# RTS5921 register map
Vendor: Realtek Semiconductor Corp.; Series: RTS5921 Series; File version: 0.01
CPU: ARMV8MBL r0p0, little endian, MPU, no FPU, VTOR, 3 interrupt priority bits
Registers are 32-bit, read-write, reset 0x0 unless marked. A register's access mark holds for its fields unless they carry their own. Offsets are from the block's base; [hi:lo] are bit positions; {n}, {i} and the like mark numbered series.

## GPIO — GPIO Controller
Base 0x40110000
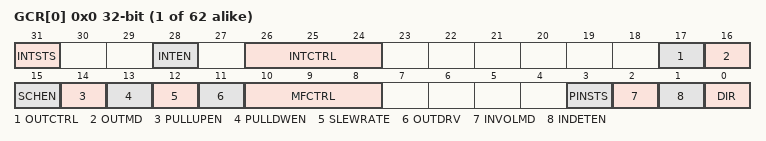
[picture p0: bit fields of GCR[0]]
{0x0+4i} GCR[{i}] (i=0..61) — CONTROL REGISTER
  [31] INTSTS write-1-clears — Interrupt Status
    0=NOT_OCCURRED (GPIO interrupt is not occurred); 1=OCCURRED (GPIO interrupt is occurred)
  [28] INTEN — Interrupt Enable
    0=DISABLE (Disable interrupt); 1=ENABLE (Enable interrupt)
  [26:24] INTCTRL — Type of GPIO Interrupt
    0=POSTIVE (Trigger interrupt when positive edge occurred); 1=NEGATIVE (Trigger interrupt when negative edge occurred); 2=DUAL (Trigger interrupt when positive/negative edge occurred); 3=LOW (Trigger interrupt when low-level occurred); 4=HIGH (Trigger interrupt when high-level occurred)
  [17] OUTCTRL — Output Control
    0=LOW (Output low); 1=HIGH (Output high)
  [16] OUTMD — Output Mode Selection
    0=PUSH_PULL (Push-pull mode); 1=OPEN_DRAIN (Open-drain mode)
  [15] SCHEN — Schmitter-Trigger Enable
    0=DISABLE (Disable schmitter-trigger); 1=ENABLE (Enable schmitter-trigger)
  [14] PULLUPEN — Internal Pull-Up Resistor Enable
    0=DISABLE (Disable internal pull-up resistor); 1=ENABLE (Enable internal pull-up resistor)
  [13] PULLDWEN — Internal Pull-Down Resistor Enable
    0=DISABLE (Disable internal pull-down resistor); 1=ENABLE (Enable internal pull-down resistor)
  [12] SLEWRATE — Slew Rate Selection
    0=FAST (Fast slew-rate); 1=SLOW (Slow slew-rate)
  [11] OUTDRV — Driving Current Selection
    0=LOW (Low driving capability); 1=HIGH (High driving capability)
  [10:8] MFCTRL — Multiple Function Control
    {v}=FUN{v} (Select function[{v}]) (v=0..3)
  [3] PINSTS ro — Status of GPIO Pin
    0=LOW (Pin status is low); 1=HIGH (Pin status is high)
  [2] INVOLMD — Input Voltage Mode
    0=3V3 (3V3 voltage input); 1=1V8 (1V8 voltage input)
  [1] INDETEN — Input Detection Enable
    0=DISABLE (Disable input detection); 1=ENABLE (Enable input detection)
  [0] DIR — Direction
    0=INPUT (Intput mode); 1=OUTPUT (Output mode)

## LED0 — PWM LED Controller
Base 0x40121000
Same registers: LED1 0x40121020
0x00 MODE
  [1:0] SEL — Mode Selection
    0=OFF (PWMLED ouput is off); 1=BREATHING (PWMLED is under breathing mode); 2=BLINKING (PWMLED is under blinking mode); 3=ALWAYS_ON (PWMLED ouput is always on)
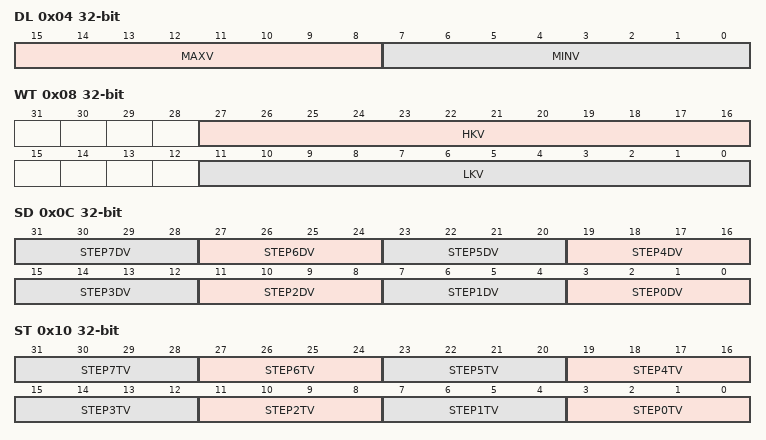
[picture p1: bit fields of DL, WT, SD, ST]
0x04 DL — DUTY LIMIT REGISTER
  [15:8] MAXV — Maximum Duty Cycle
  [7:0] MINV — Minimum Duty Cycle
0x08 WT — WAIT TIME REGISTER
  [27:16] HKV — High wait-time
  [11:0] LKV — Low wait-time
0x0C SD — STEP DUTY REGISTER
  [4n+3:4n] STEP{n}DV (n=0..7) — Step{n} Duty Value
0x10 ST — STEP TIME REGISTER
  [4n+3:4n] STEP{n}TV (n=0..7) — Step{n} Time Value
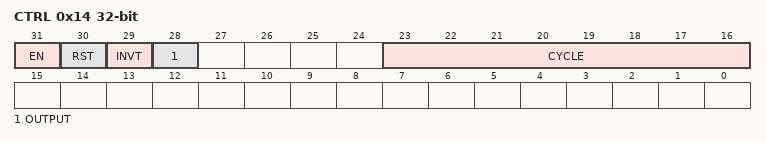
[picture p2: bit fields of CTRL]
0x14 CTRL — CONTROL REGISTER
  [31] EN — Enable PWMLED Controller
    0=DISABLE (Disable PWMLED Controller); 1=ENABLE (Enable PWMLED Controller)
  [30] RST — Reset PWM LED Controller
    0=DO_NOTHING; 1=RESET (Reset PWM LED controller)
  [29] INVT — Output Inverter Control
    0=NORMAL (PWM output is not invert); 1=INVERT (PWM output is invert)
  [28] OUTPUT — Control the output method
    0=ALWAYS_ON (Output is always on); 1=BY_CYCLE (Output is stop when entire cycle is finished)
  [23:16] CYCLE — The number of output cycle

## PWM0 — PWM Controller
Base 0x40121040
Same registers: PWM{n} {0x40121040+0x20*n} (n=1..29)
0x00 DUTY — PWM DUTY REGISTER
0x04 DIV — PWM DIVIDER REGISTER
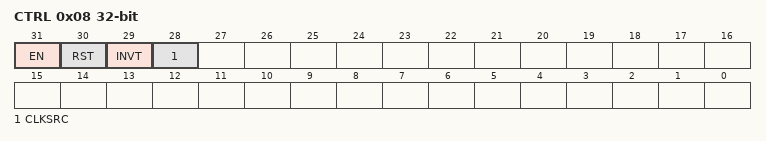
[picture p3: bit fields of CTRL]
0x08 CTRL — PWM CONTROL REGISTER
  [31] EN — Enable PWM Controller
    0=DISABLE (Disable PWM Controller); 1=ENABLE (Enable PWM Controller)
  [30] RST — Reset PWM Controller
    0=DO_NOTHING; 1=RESET (Reset PWM controller)
  [29] INVT — Output Inverter Control
    0=NORMAL (PWM output is not invert); 1=INVERT (PWM output is invert)
  [28] CLKSRC — Clock Source Selection
    0=PLL (PWM clock source is from PLL); 1=RC32K (PWM clock source is from RC32K)

## TMR0 — Timer Controller
Base 0x40121400
Same registers: TMR1 0x40121420, TMR2 0x40121440, TMR3 0x40121460
0x00 LDCNT — LOAD COUNTER REGISTER
0x04 CNT — CURRENT COUNTER REGISTER
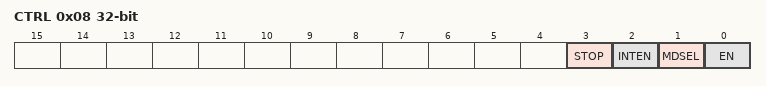
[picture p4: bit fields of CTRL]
0x08 CTRL — CONTROL REGISTER
  [3] STOP — Stop timer
    0=DISABLE (Resume timer); 1=ENABLE (Stop timer)
  [2] INTEN — Enable Timer Interrupt
    0=DISABLE (Disable timer interrupt); 1=ENABLE (Enable timer interrupt)
  [1] MDSEL — Timer Operating Mode Selection
    0=ONE_SHOT (Timer is operate at one-shot mode); 1=CONTINUOUS (Timer is operate at continuous mode)
  [0] EN — Enable Timer Contoller
    0=DISABLE (Disable timer controller); 1=ENABLE (Enable timer controller)
0x0C INTSTS — INTERRUPT STATUS REGISTER
  [0] STS write-1-clears — Timer Interrupt Status
    0=NOT_OCCURRED (Timer interrupt is not occurred); 1=OCCURRED (Timer interrupt is occurred)

## CRC32 — CRC32 Engine
Base 0x40122000
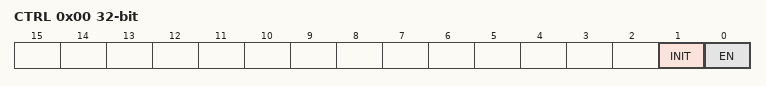
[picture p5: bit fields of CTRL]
0x00 CTRL — Control register
  [1] INIT — Initialize checksum. Resets CHKSUM to 0xFFFFFFFF and auto-clears to '0'.
  [0] EN — Enable CRC32. Controls whether CRC32 is enabled or disabled.
    0=DISABLE (Disable CRC32); 1=ENABLE (Enable CRC32)
0x04 INPUT — Data input register for CRC32 computation.
  [31:0] INPUT — Data input for CRC32.
0x08 RESULT — CRC32 Result Register
0x0C CHKSUM — Checksum Result Register

## THERMAL_CAL — Thermal Calibration Engine
Base 0x40122600
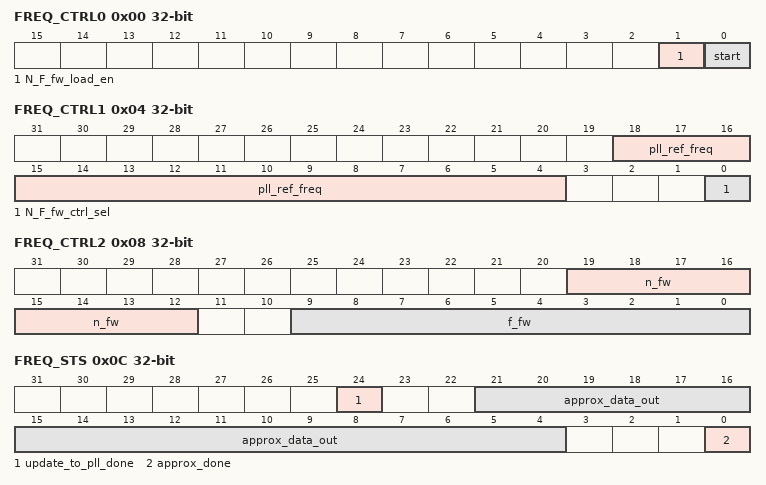
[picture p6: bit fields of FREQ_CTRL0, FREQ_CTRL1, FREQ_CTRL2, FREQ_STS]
0x00 FREQ_CTRL0 — Frequency Control Register #0
  [1] N_F_fw_load_en — Update n_fw/f_fw to SDM module, N_F_fw_load_en need to maintain at least 1.3 us and then set to 0
  [0] start — Trigger to compute 480/pll_ref_freq
0x04 FREQ_CTRL1 — Frequency Control Register #1
  [18:4] pll_ref_freq — N.F = 2.13, default = 15b10.0010111000010 = 2.18M HZ
  [0] N_F_fw_ctrl_sel — 0: PLL N,F code from n_fw,f_fw, 1: PLL N,F code from hardware approximation
0x08 FREQ_CTRL2 — Frequency Control Register #2
  [19:12] n_fw — (unsigned) N code to PLL, default = 8'b11011010 (218). Set n_fw after N_F_fw_load_en = 1 1.3us and before set N_F_fw_load_en = 0
  [9:0] f_fw — (unsigned) F code to PLL, default = 10'b0000000000 (f_fw/1024 =0). Set f_fw after N_F_fw_load_en = 1 1.3us and before set N_F_fw_load_en = 0
0x0C FREQ_STS — Frequency Status Register
  [24] update_to_pll_done — done flag for update N/F to SDM module
  [21:4] approx_data_out — (unsigned) N.F = 8.10, 480/pll_ref_freq result
  [0] approx_done — done flag for 480/pll_ref_freq
0x10 CP_CTRL0 — CP Control Register #0
  [0] start_lc_cnt — trigger to use CLK_2P2M_USB2 (LC_REF_24M/11) to count external reference clock
0x14 CP_CTRL1 — CP Control Register #1
  [3:0] ref_clk_cycles_num — total count (ref_clk_cycle_num + 1) external reference clock cycles
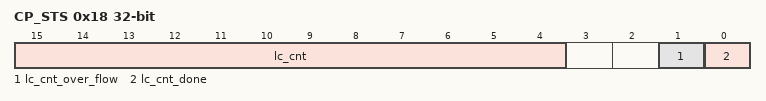
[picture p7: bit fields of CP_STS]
0x18 CP_STS — CP Status Register
  [15:4] lc_cnt — lc counter value
  [1] lc_cnt_over_flow — lc counter over flow flag
  [0] lc_cnt_done — done flag for lc count
